# EFM32PG22C200F512IM32 register map
Vendor: Silicon Labs; Series: EFM32; File version: C
Registers are 32-bit, read-write, reset 0x0 unless marked. A register's access mark holds for its fields unless they carry their own. Offsets are from the block's base; [hi:lo] are bit positions; {n}, {i} and the like mark numbered series.

## SYSCFG_S_CFGNS — SYSCFG_S_CFGNS Registers
Base 0x40078000
Same registers: SYSCFG_NS_CFGNS 0x50078000
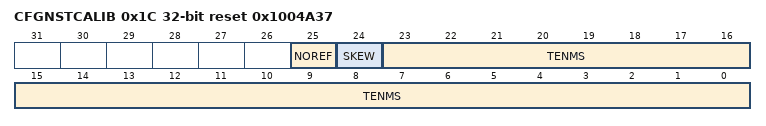
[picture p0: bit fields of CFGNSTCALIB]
0x1C CFGNSTCALIB reset 0x1004A37 — Configure to define the system tick for the M33.
  [25] NOREF — No Reference
    0=REF (Reference clock is implemented); 1=NOREF (Reference clock is not implemented)
  [24] SKEW
  [23:0] TENMS — Ten Milliseconds
0x600 ROOTNSDATA0 — Generic data space for user to pass to root, e.g., address of struct in mem
  [31:0] DATA
0x604 ROOTNSDATA1 — Generic data space for user to pass to root, e.g., address of struct in mem
  [31:0] DATA

## SYSCFG_S — SYSCFG_S Registers
Base 0x4007C000
Same registers: SYSCFG_NS 0x5007C000
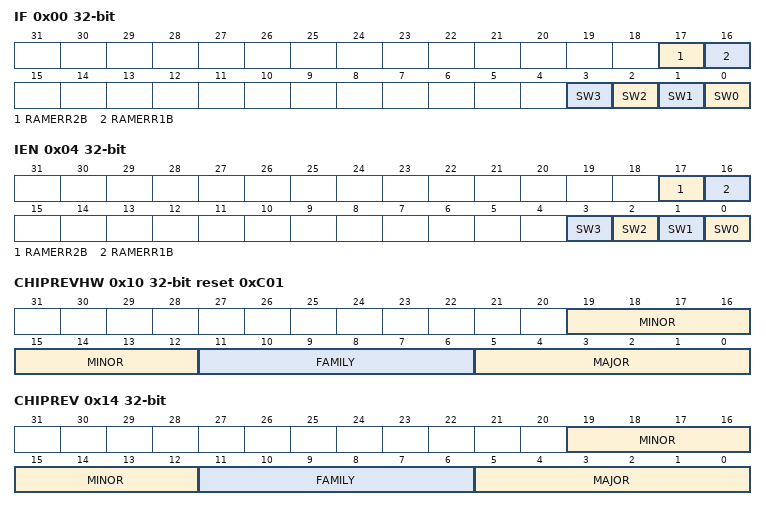
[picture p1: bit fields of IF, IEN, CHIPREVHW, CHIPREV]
0x00 IF — Read to get system status.
  [17] RAMERR2B — RAM 2-Bit Error Interrupt Flag
  [16] RAMERR1B — RAM 1-Bit Error Interrupt Flag
  [n] SW{n} (n=0..3) — Software Interrupt {n}
0x04 IEN — Write to enable interrupts.
  [17] RAMERR2B — RAM 2-bit Error Interrupt Enable
  [16] RAMERR1B — RAM 1-bit Error Interrupt Enable
  [n] SW{n} (n=0..3) — Software interrupt {n}
0x10 CHIPREVHW reset 0xC01 — Read to get the hard-wired chip revision.
  [19:12] MINOR — Hardwired Chip Revision Minor value
  [11:6] FAMILY — Hardwired Chip Family value
  [5:0] MAJOR — Hardwired Chip Revision Major value
0x14 CHIPREV — Read to get the chip revision programmed by feature configuration.
  [19:12] MINOR — Chip Revision Minor value
  [11:6] FAMILY — Chip Family value
  [5:0] MAJOR — Chip Revision Major value
0x20 CFGSYSTIC — Configure the source of the system tick for the M33.
  [0] SYSTICEXTCLKEN — SysTick External Clock Enable
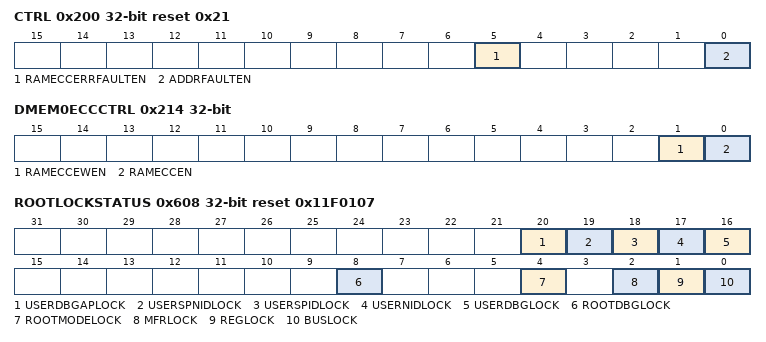
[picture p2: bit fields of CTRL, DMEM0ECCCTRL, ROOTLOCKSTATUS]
0x200 CTRL reset 0x21 — Configure to provide general RAM configuration.
  [5] RAMECCERRFAULTEN — Two bit ECC Error Bus Fault Response Enable
  [0] ADDRFAULTEN — Invalid Address Bus Fault Response Enable
0x208 DMEM0RETNCTRL — Configure to provide general RAM retention configuration.
  [1:0] RAMRETNCTRL — DMEM0 blockset retention control
    0=ALLON (None of the RAM blocks powered down); 1=BLK0 (Power down RAM block 0); 2=BLK1 (Power down RAM block 1)
0x210 DMEM0ECCADDR ro — Read to get status of the DMEM0 ECC error address.
  [31:0] DMEM0ECCADDR — DMEM0 RAM ECC Error Address
0x214 DMEM0ECCCTRL — Configure to set RAM ECC control.
  [1] RAMECCEWEN — RAM ECC Error Writeback Enable
  [0] RAMECCEN — RAM ECC Enable
0x600 ROOTDATA0 — Data in this register is passed to the trusted root firmware upon reset.
  [31:0] DATA
0x604 ROOTDATA1 — Data in this register is passed to the trusted root firmware upon reset.
  [31:0] DATA
0x608 ROOTLOCKSTATUS ro reset 0x11F0107 — This register returns the status of the SE managed locks.
  [20] USERDBGAPLOCK — User Debug Access Port Lock
  [19] USERSPNIDLOCK — User Secure Non-invasive Debug Lock
  [18] USERSPIDLOCK — User Secure Invasive Debug Lock
  [17] USERNIDLOCK — User Non-invasive Debug Lock
  [16] USERDBGLOCK — User Invasive Debug Lock
  [8] ROOTDBGLOCK — Root Debug Lock
  [4] ROOTMODELOCK
  [2] MFRLOCK — Manufacture Lock
  [1] REGLOCK — Register Lock
  [0] BUSLOCK

## BURAM_S — BURAM_S Registers
Base 0x40080000
Same registers: BURAM_NS 0x50080000
{0x0+4i} RET{i}_REG (i=0..31)
  [31:0] RETREG — Latch based Retention register

## GPCRC_S — GPCRC_S Registers
Base 0x40088000
Same registers: GPCRC_NS 0x50088000
0x00 IPVERSION ro
  [31:0] IPVERSION — IP Version ID
0x04 EN
  [0] EN — CRC Enable
    0=DISABLE (Disable CRC function. Reordering functions are still available. Only BITREVERSE and BYTEREVERSE bits are configurable in this mode.); 1=ENABLE (Writes to INPUTDATA registers will result in CRC operations.)
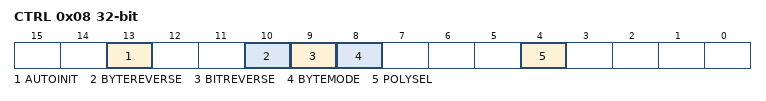
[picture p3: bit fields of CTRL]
0x08 CTRL
  [13] AUTOINIT — Auto Init Enable
  [10] BYTEREVERSE — Byte Reverse Mode
    0=NORMAL (No reverse: B3, B2, B1, B0); 1=REVERSED (Reverse byte order. For 32-bit: B0, B1, B2, B3; For 16-bit: 0, 0, B0, B1)
  [9] BITREVERSE — Byte-level Bit Reverse Enable
    0=NORMAL (No reverse); 1=REVERSED (Reverse bit order in each byte)
  [8] BYTEMODE — Byte Mode Enable
  [4] POLYSEL — Polynomial Select
    0=CRC32 (CRC-32 (0x04C11DB7) polynomial selected); 1=CRC16 (16-bit CRC programmable polynomial selected)
0x0C CMD wo
  [0] INIT — Initialization Enable
0x10 INIT
  [31:0] INIT — CRC Initialization Value
0x14 POLY
  [15:0] POLY — CRC Polynomial Value
0x18 INPUTDATA wo
  [31:0] INPUTDATA — Input Data for 32-bit
0x1C INPUTDATAHWORD wo
  [15:0] INPUTDATAHWORD — Input Data for 16-bit
0x20 INPUTDATABYTE wo
  [7:0] INPUTDATABYTE — Input Data for 8-bit
0x24 DATA ro
  [31:0] DATA — CRC Data Register
0x28 DATAREV ro
  [31:0] DATAREV — Data Reverse Value
0x2C DATABYTEREV ro
  [31:0] DATABYTEREV — Data Byte Reverse Value
